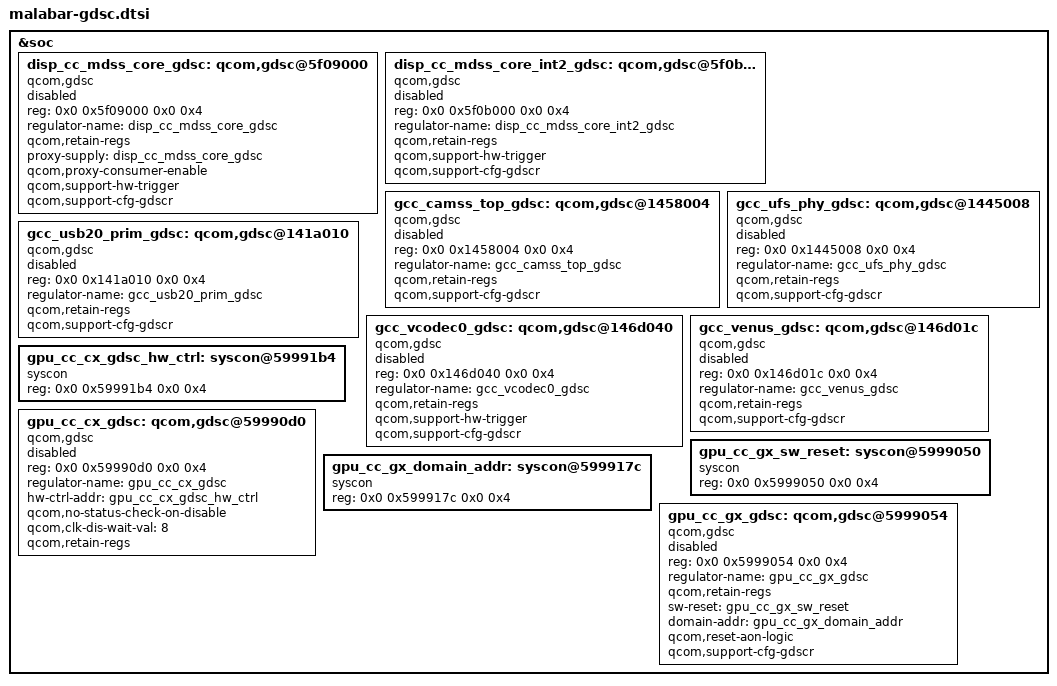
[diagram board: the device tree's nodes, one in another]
// SPDX-License-Identifier: BSD-3-Clause
/*
 * Copyright (c) Qualcomm Technologies, Inc. and/or its subsidiaries.
 */

&soc {
	/* DISP_CC GDSCs */
	disp_cc_mdss_core_gdsc: qcom,gdsc@5f09000 {
		compatible = "qcom,gdsc";
		reg = <0x0 0x5f09000 0x0 0x4>;
		regulator-name = "disp_cc_mdss_core_gdsc";
		qcom,retain-regs;
		proxy-supply = <&disp_cc_mdss_core_gdsc>;
		qcom,proxy-consumer-enable;
		qcom,support-hw-trigger;
		qcom,support-cfg-gdscr;
		status = "disabled";
	};

	disp_cc_mdss_core_int2_gdsc: qcom,gdsc@5f0b000 {
		compatible = "qcom,gdsc";
		reg = <0x0 0x5f0b000 0x0 0x4>;
		regulator-name = "disp_cc_mdss_core_int2_gdsc";
		qcom,retain-regs;
		qcom,support-hw-trigger;
		qcom,support-cfg-gdscr;
		status = "disabled";
	};

	/* GCC GDSCs */
	gcc_camss_top_gdsc: qcom,gdsc@1458004 {
		compatible = "qcom,gdsc";
		reg = <0x0 0x1458004 0x0 0x4>;
		regulator-name = "gcc_camss_top_gdsc";
		qcom,retain-regs;
		qcom,support-cfg-gdscr;
		status = "disabled";
	};

	gcc_ufs_phy_gdsc: qcom,gdsc@1445008 {
		compatible = "qcom,gdsc";
		reg = <0x0 0x1445008 0x0 0x4>;
		regulator-name = "gcc_ufs_phy_gdsc";
		qcom,retain-regs;
		qcom,support-cfg-gdscr;
		status = "disabled";
	};

	gcc_usb20_prim_gdsc: qcom,gdsc@141a010 {
		compatible = "qcom,gdsc";
		reg = <0x0 0x141a010 0x0 0x4>;
		regulator-name = "gcc_usb20_prim_gdsc";
		qcom,retain-regs;
		qcom,support-cfg-gdscr;
		status = "disabled";
	};

	gcc_vcodec0_gdsc: qcom,gdsc@146d040 {
		compatible = "qcom,gdsc";
		reg = <0x0 0x146d040 0x0 0x4>;
		regulator-name = "gcc_vcodec0_gdsc";
		qcom,retain-regs;
		qcom,support-hw-trigger;
		qcom,support-cfg-gdscr;
		status = "disabled";
	};

	gcc_venus_gdsc: qcom,gdsc@146d01c {
		compatible = "qcom,gdsc";
		reg = <0x0 0x146d01c 0x0 0x4>;
		regulator-name = "gcc_venus_gdsc";
		qcom,retain-regs;
		qcom,support-cfg-gdscr;
		status = "disabled";
	};

	/* GPU_CC GDSCs */
	gpu_cc_cx_gdsc_hw_ctrl: syscon@59991b4 {
		compatible = "syscon";
		reg = <0x0 0x59991b4 0x0 0x4>;
	};

	gpu_cc_cx_gdsc: qcom,gdsc@59990d0 {
		compatible = "qcom,gdsc";
		reg = <0x0 0x59990d0 0x0 0x4>;
		regulator-name = "gpu_cc_cx_gdsc";
		hw-ctrl-addr = <&gpu_cc_cx_gdsc_hw_ctrl>;
		qcom,no-status-check-on-disable;
		qcom,clk-dis-wait-val = <8>;
		qcom,retain-regs;
		status = "disabled";
	};

	gpu_cc_gx_sw_reset: syscon@5999050 {
		compatible = "syscon";
		reg = <0x0 0x5999050 0x0 0x4>;
	};

	gpu_cc_gx_domain_addr: syscon@599917c {
		compatible = "syscon";
		reg = <0x0 0x599917c 0x0 0x4>;
	};

	gpu_cc_gx_gdsc: qcom,gdsc@5999054 {
		compatible = "qcom,gdsc";
		reg = <0x0 0x5999054 0x0 0x4>;
		regulator-name = "gpu_cc_gx_gdsc";
		qcom,retain-regs;
		sw-reset = <&gpu_cc_gx_sw_reset>;
		domain-addr = <&gpu_cc_gx_domain_addr>;
		qcom,reset-aon-logic;
		qcom,support-cfg-gdscr;
		status = "disabled";
	};
};
